# TLE985x register map
Vendor: Infineon Technologies AG; File version: 1.3
CPU: CM0 r0p0, little endian, no MPU, no FPU, 2 interrupt priority bits
Registers are 32-bit, read-write, no defined reset value unless marked. A register's access mark holds for its fields unless they carry their own. Offsets are from the block's base; [hi:lo] are bit positions; {n}, {i} and the like mark numbered series; 'fields as' and 'values as' point back to an identical list.

## PMU
Base 0x50004000
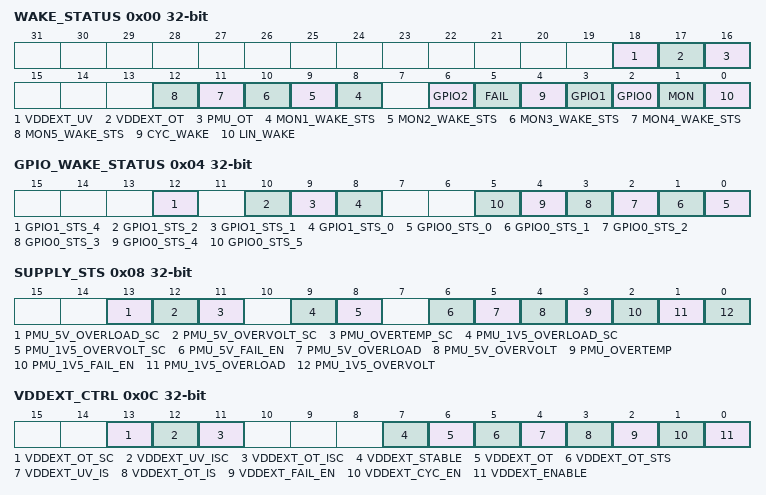
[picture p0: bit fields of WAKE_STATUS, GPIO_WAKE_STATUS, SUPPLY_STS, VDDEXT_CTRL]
0x00 WAKE_STATUS ro — Main wake status register
  [18] VDDEXT_UV — Wake VDDEXT Undervoltage
    0=No wake-up detected; 1=wake-up detected
  [17] VDDEXT_OT — Wake VDDEXT Overtemperature
    0=No wake-up detected; 1=wake-up detected
  [16] PMU_OT — Wake PMU Overtemperature
    0=No wake-up detected; 1=wake-up detected
  [n+7] MON{n}_WAKE_STS (n=1..5) — Status of MON{n}
    0=No wake-up detected; 1=wake-up detected
  [6] GPIO2 — Wake-up via GPIO2 which is a logical OR combination of all Wake_STS_GPIO2 bits
    0=No Wake-up occurred; 1=Wake-up occurred
  [5] FAIL — Wake-up after any Fail, which is a logical OR combination of PMU_OT, VDDEXT_OT, VDDEXT_UV
    0=No Wake-up occurred; 1=Wake-up occurred
  [4] CYC_WAKE — Wake-up caused by Cyclic Wake
    0=No Wake-up occurred; 1=Wake-up occurred
  [3] GPIO1 — Wake-up via GPIO1 which is a logical OR combination of all Wake_STS_GPIO1 bits
    0=No Wake-up occurred; 1=Wake-up occurred
  [2] GPIO0 — Wake-up via GPIO0 which is a logical OR combination of all Wake_STS_GPIO0 bits
    0=No Wake-up occurred; 1=Wake-up occurred
  [1] MON — Wake-up via MON which is a logical OR combination of all Wake_STS_MON bits
    0=No Wake-up occurred; 1=Wake-up occurred
  [0] LIN_WAKE — Wake-up via LIN- Message
    0=No Wake-up occurred; 1=Wake-up occurred
0x04 GPIO_WAKE_STATUS ro — GPIO Port wake status register
  [all] fields
    0=No wake-up detected; 1=wake-up detected
  [12] GPIO1_STS_4 — Wake GPIO1_4
  [10] GPIO1_STS_2 — Wake GPIO1_2
  [9] GPIO1_STS_1 — Wake GPIO1_1
  [8] GPIO1_STS_0 — Wake GPIO1_0
  [n] GPIO0_STS_{n} (n=0..5) — Status of GPIO0_{n}
0x08 SUPPLY_STS access per field — Voltage Reg Status Register
  [13] PMU_5V_OVERLOAD_SC wo — Overload at VDDP regulator Status clear
    0=No Clear (Overload status not cleared); 1=Clear (Overload status cleared)
  [12] PMU_5V_OVERVOLT_SC wo — Overvoltage at VDDP regulator Status clear
    0=No Clear (Overvoltage status not cleared); 1=Clear (Overvoltage status cleared)
  [11] PMU_OVERTEMP_SC wo — Overtemperature Status clear
    0=No Clear (Overtemperature status not cleared); 1=Clear (Overtemperature status cleared)
  [9] PMU_1V5_OVERLOAD_SC wo — Overload at VDDC regulator Status clear
    values as PMU_5V_OVERLOAD_SC
  [8] PMU_1V5_OVERVOLT_SC wo — Overvoltage at VDDC regulator Status clear
    values as PMU_5V_OVERVOLT_SC
  [6] PMU_5V_FAIL_EN rw — Enabling of VDDP status information as interrupt source
    0=Disable (No interrupts are generated); 1=Enable (Interrupts are generated)
  [5] PMU_5V_OVERLOAD ro — Overload at VDDP regulator
    0=No overload; 1=Overload
  [4] PMU_5V_OVERVOLT ro — Overvoltage at VDDP regulator
    0=No overvoltage; 1=Overvoltage
  [3] PMU_OVERTEMP ro — PMU Overtemperature
    0=No overtemperature; 1=Overtemperature
  [2] PMU_1V5_FAIL_EN rw — Enabling of VDDC status information as interrupt source
    values as PMU_5V_FAIL_EN
  [1] PMU_1V5_OVERLOAD ro — Overload at VDDC regulator
    0=No overload; 1=Overload
  [0] PMU_1V5_OVERVOLT ro — Overvoltage at VDDC regulator
    0=No overvoltage; 1=Overvoltage
0x0C VDDEXT_CTRL access per field — VDDEXT Control
  [13] VDDEXT_OT_SC wo — VDDEXT Supply Overtemperature Status clear
    1=No Clear (VDDEXT Overtemperature status not cleared); 0=Clear (VDDEXT Overtemperature status cleared)
  [12] VDDEXT_UV_ISC wo — VDDEXT Supply Undervoltage Interrupt Status clear
    1=No Clear (VDDEXT Undervoltage not cleared); 0=Clear (VDDEXT Undervoltage cleared)
  [11] VDDEXT_OT_ISC wo — VDDEXT Supply Overtemperature Interrupt Status clear
    1=No Clear (VDDEXT OverTemperature not cleared); 0=Clear (VDDEXT OverTemperature cleared)
  [7] VDDEXT_STABLE ro — VDDEXT Supply Stable
    0=VDDEXT not in stable condition; 1=VDDEXT in stable condition
  [6] VDDEXT_OT ro — VDDEXT Supply Overtemperature
    0=VDDEXT not in overtemperature condition; 1=VDDEXT in overtemperature condition
  [5] VDDEXT_OT_STS ro — VDDEXT Supply Overtemperature Status
    values as VDDEXT_OT
  [4] VDDEXT_UV_IS ro — VDDEXT Supply Undervoltage Interrupt Status
    0=VDDEXT not in undervoltage condition; 1=VDDEXT in undervoltage condition
  [3] VDDEXT_OT_IS ro — VDDEXT Supply OverTemperature Interrupt Status
    0=VDDEXT no overtemperature condition; 1=VDDEXT overtemperature condition
  [2] VDDEXT_FAIL_EN rw — Enabling of VDDEXT Supply status information as interrupt source
    0=Disable (VDDEXT fail interrupts are disable); 1=Enable (VDDEXT fail Interrupts are enable)
  [1] VDDEXT_CYC_EN rw — VDDEXT Supply for Cyclic Sense Enable
    0=Disable (VDDEXT for cyclic sense disable); 1=Enable (VDDEXT for cyclic sense enable)
  [0] VDDEXT_ENABLE rw — VDDEXT Supply Enable
    0=Disable (VDDEXT Supply disable); 1=Enable (VDDEXT supply enable)
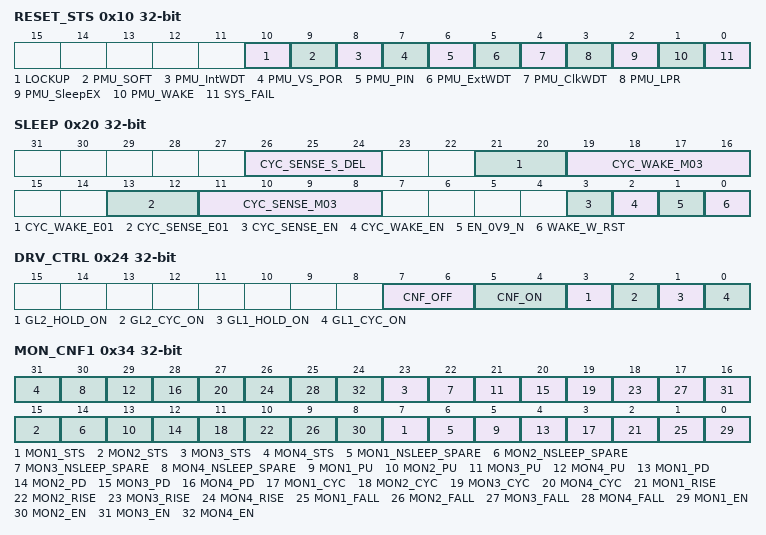
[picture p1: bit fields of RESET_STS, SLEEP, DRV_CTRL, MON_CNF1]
0x10 RESET_STS — Reset Status Register
  [10] LOCKUP — Lockup-Reset Flag
    0=No Reset (No Lockup-Reset executed); 1=Reset (Lockup-Reset executed)
  [9] PMU_SOFT — Soft-Reset Flag
    0=No Reset (No Soft-Reset executed); 1=Reset (Soft-Reset executed)
  [8] PMU_IntWDT — Internal Watchdog Reset Flag
    0=No Reset (No Internal Watchdog reset executed); 1=Reset (Internal Watchdog reset executed)
  [7] PMU_VS_POR — Power-On Reset Flag
    0=No Reset (No Power-On reset executed); 1=Reset (Power-On reset executed)
  [6] PMU_PIN — PIN-Reset Flag
    0=No Reset (No PIN-Reset executed); 1=Reset (PIN-Reset executed)
  [5] PMU_ExtWDT — External Watchdog (WDT1) Reset Flag
    0=No Reset (No External Watchdog reset executed); 1=Reset (External Watchdog reset executed)
  [4] PMU_ClkWDT — Clock Watchdog (CLKWDT) Reset Flag
    0=No Reset (No Clock Watchdog reset executed); 1=Reset (Clock Watchdog reset executed)
  [3] PMU_LPR — Low Priority Resets (see PMU_RST_STS2)
    0=No Reset (No Low Priority reset executed); 1=Reset (Low Priority reset executed)
  [2] PMU_SleepEX — Flag which indicates a reset caused by Sleep-Exit
    0=No reset caused by Sleep-Exit executed; 1=Reset caused by Sleep-Exit executed
  [1] PMU_WAKE — Flag which indicates a reset caused by Stop-Exit
    0=No reset caused by Stop-Exit executed; 1=Reset caused by Stop-Exit executed
  [0] SYS_FAIL — Flag which indicates a reset caused by a System Fail reported in the corresponding Fail Register
    0=No reset caused by System Fail executed; 1=Reset caused by System Fail executed
0x20 SLEEP — PMU Sleep Behavior Register
  [26:24] CYC_SENSE_S_DEL — Sample Delay in Cyclic Sense
    0=10 us typ; 1=20 us typ; 2=30 us typ; 3=40 us typ; 4=60 us typ; 5=80 us typ; 6=100 us typ; 7=150 us typ
  [21:20] CYC_WAKE_E01 — Exponent
    {v}=Exponent value is {v} (v=0..3)
  [19:16] CYC_WAKE_M03 — Mantissa
    0=Mantissa value is 1; 15=Mantissa value is 16
  [13:12] CYC_SENSE_E01 — Exponent
    {v}=Exponent value is {v} (v=0..3)
  [11:8] CYC_SENSE_M03 — Mantissa
    0=Mantissa value is 1; 15=Mantissa value is 16
  [3] CYC_SENSE_EN — Enabling Cyclic Sense
    0=Disable (Cyclic Sense disabled); 1=Enable (Cyclic Sense enabled)
  [2] CYC_WAKE_EN — Enabling Cyclic Wake
    0=Disable (Cyclic Wake disabled); 1=Enable (Cyclic Wake enabled)
  [1] EN_0V9_N — Enables the reduction of the VDDC regulator output to 0.9 V during Stop-Mode
    0=Enable (Output voltage reduction enabled); 1=Disable (Output voltage reduction disabled)
  [0] WAKE_W_RST — Wake-up with reset execution
    0=No Reset (Stop-Exit without reset execution); 1=Reset (Stop-Exit with reset execution)
0x24 DRV_CTRL — PMU Bridge Driver Control
  [7:6] CNF_OFF — CNF_OFF Function
    0=400 us; 1=800 us; 2=2000 us; 3=4000 us
  [5:4] CNF_ON — CNF_ON Function
    0=50 us; 1=100 us; 2=200 us; 3=400 us
  [3] GL2_HOLD_ON — GL2 Hold Mode On
    0=Disable; 1=Enable
  [2] GL2_CYC_ON — GL2 Cyclic On
    0=Disable; 1=Enable
  [1] GL1_HOLD_ON — GL1 Hold Mode On
    0=Disable; 1=Enable
  [0] GL1_CYC_ON — GL1 Cyclic On
    0=Disable; 1=Enable
0x34 MON_CNF1 access per field — Settings Monitor
  [8n-1] MON{n}_STS ro (n=1..4) — MON{n} Status Input
    0=Low (MON input has low status); 1=High (MON input has high status)
  [8n-2] MON{n}_NSLEEP_SPARE rw (n=1..4) — MON{n} Sleep Bit
    0=Sleep Mode (internal MON output forced to 0); 1=Active Mode (internal MON output not forced to 0)
  [8n-3] MON{n}_PU rw (n=1..4) — Pull-Up Current Source for MON{n} Input Enable
    0=Disable (Pull-up source disabled); 1=Enable (Pull-up source enabled)
  [8n-4] MON{n}_PD rw (n=1..4) — Pull-Down Current Source for MON{n} Input Enable
    0=Disable (Pull-down source disabled); 1=Enable (Pull-down source enabled)
  [8n-5] MON{n}_CYC rw (n=1..4) — MON{n} for Cycle Sense Enable
    0=Disable (Cycle Sense disabled); 1=Enable (Cycle Sense enabled)
  [8n-6] MON{n}_RISE rw (n=1..4) — MON{n} Wake-up on Rising Edge Enable
    0=Disable (Wake-up disabled); 1=Enable (Wake-up enabled)
  [8n-7] MON{n}_FALL rw (n=1..4) — MON{n} Wake-up on Falling Edge Enable
    0=Disable (Wake-up disabled); 1=Enable (Wake-up enabled)
  [8n-8] MON{n}_EN rw (n=1..4) — MON{n} Enable
    0=Disable (MON{n} disabled); 1=Enable (MON{n} enabled)
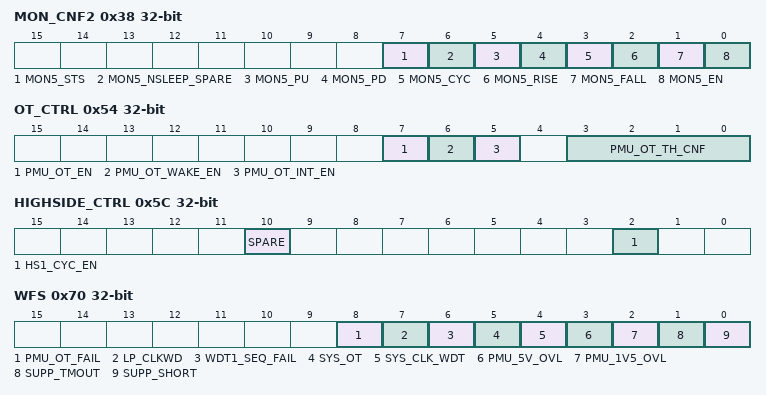
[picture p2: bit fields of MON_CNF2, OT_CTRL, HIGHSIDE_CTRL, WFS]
0x38 MON_CNF2 access per field — Settings Monitor
  [7] MON5_STS ro — MON5 Status Input
    values as MON_CNF1.MON1_STS
  [6] MON5_NSLEEP_SPARE rw — MON5 Sleep Bit
    values as MON_CNF1.MON1_NSLEEP_SPARE
  [5] MON5_PU rw — Pull-Up Current Source for MON5 Input Enable
    values as MON_CNF1.MON1_PU
  [4] MON5_PD rw — Pull-Down Current Source for MON5 Input Enable
    values as MON_CNF1.MON1_PD
  [3] MON5_CYC rw — MON5 for Cycle Sense Enable
    values as MON_CNF1.MON1_CYC
  [2] MON5_RISE rw — MON5 Wake-up on Rising Edge Enable
    0=Disable (Wake-up disabled); 1=Enable (Wake-up enabled)
  [1] MON5_FALL rw — MON5 Wake-up on Falling Edge Enable
    0=Disable (Wake-up disabled); 1=Enable (Wake-up enabled)
  [0] MON5_EN rw — MON5 Enable
    0=Disable (MON5 disabled); 1=Enable (MON5 enabled)
0x50 LIN_WAKE_EN — LIN Wake Enable
  [7] LIN_WAKE_EN — Lin Wake enable
    0=Wake Disabled; 1=Wake enabled
0x54 OT_CTRL — Overtemperature Control Register
  [7] PMU_OT_EN — PMU Overtemperature Detection Enable
    0=Disable (Overtemperature detection disabled); 1=Enable (Overtemperature detection enabled)
  [6] PMU_OT_WAKE_EN — PMU Wake On Overtemperature Enable
    0=Disable (no Wake-Up on OT condition); 1=Enable (Wake-Up on OT condition)
  [5] PMU_OT_INT_EN — PMU Overtemperature Interrupt Enable
    0=No Interrupt (Interrupt on OT disabled); 1=Interrupt on OT enabled
  [3:0] PMU_OT_TH_CNF — PMU Overtemperature threshold
    0=131 degree C; 1=136 degree C; 2=141 degree C; 3=146 degree C; 4=152 degree C; 5=157 degree C; 6=163 degree C; 7=169 degree C; 8=175 degree C; 9=181 degree C; 10=187 degree C; 11=193 degree C; 12=200 degree C; 13=206 degree C; 14=214 degree C; 15=221 degree C
0x5C HIGHSIDE_CTRL — Highside Control Register
  [10] SPARE
  [2] HS1_CYC_EN — High-Side 1 switch enable for cyclic sense
    0=Disable; 1=Enable
0x6C CNF_RST_TFB — Reset Blind Time Register
  [1:0] RST_TFB — Reset Pin Blind Time Selection Bits
    0=0.5 us typ; 1=1 us typ; 2=5 us typ; 3=31 us typ
0x70 WFS ro — WFS System Fail Register
  [8] PMU_OT_FAIL — PMU Overtemperature Indication Flag
    0=No Overtemperature (PMU ok); 1=Overtemperature (PMU Overtemperature)
  [7] LP_CLKWD
    0=ok; 1=fail
  [6] WDT1_SEQ_FAIL — External Watchdog (WDT1) Sequential Fail
    0=No Fail (System working properly); 1=Sequential Watchdog Fail (5 consecutive watchdog fails)
  [5] SYS_OT — System Overtemperature Indication Flag
    0=No Overtemperature (System ok); 1=Overtemperature (System Overtemperature)
  [4] SYS_CLK_WDT — System Clock (fsys)Watchdog Fail
    0=No System Clock Fail (fsys ok); 1=System Clock Fail (fsys failed)
  [3] PMU_5V_OVL — VDDP Overload Flag
    0=No Overload (VDDP ok); 1=Overload (VDDP Overload)
  [2] PMU_1V5_OVL — VDDC Overload Flag
    0=No Overload (VDDC ok); 1=Overload (Hall VDDC Overload)
  [1] SUPP_TMOUT — Supply Time Out
    0=Main Supply ok (VDDP or VDDC are in expected range); 1=Main Supply fail (VDDP or VDDC do not have stable operating point)
  [0] SUPP_SHORT — Supply Short
    0=Main Supply ok (VDDP or VDDC are in expected range); 1=Main Supply short (VDDP or VDDC are in short circuit condition)
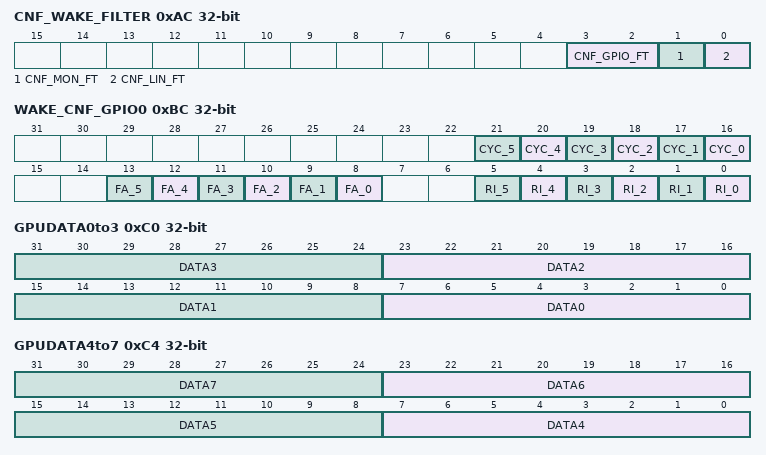
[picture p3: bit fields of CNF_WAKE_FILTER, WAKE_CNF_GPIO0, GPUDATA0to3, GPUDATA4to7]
0xAC CNF_WAKE_FILTER — PMU Wake-up Timing Register
  [3:2] CNF_GPIO_FT — Wake-up Filter time for General Purpose IO
    0=10 us filter time; 1=20 us filter time; 2=40 us filter time; 3=5 us filter time
  [1] CNF_MON_FT — Wake-up Filter time for Monitoring Inputs
    0=20 us filter time; 1=40 us filter time
  [0] CNF_LIN_FT — Wake-up Filter time for LIN WAKE
    0=50 us filter time; 1=30 us filter time
0xB4 PORCFG — POR Reset Configuration Register
  [1:0] CNF_FILT — Configuration for reset filter
0xBC WAKE_CNF_GPIO0 — Wake Configuration GPIO Port 0 Register
  [n+16] CYC_{n} (n=0..5) — GPIO0_{n} input for cycle sense enable
    1=ENABLE (input for cycle sense enabled); 0=DISABLE (input for cycle sense disabled)
  [n+8] FA_{n} (n=0..5) — Port 0_{n} Wake-up on Falling Edge enable
    1=ENABLE (wake-up enabled); 0=DISABLE (wake-up disabled)
  [n] RI_{n} (n=0..5) — Port 0_{n} Wake-up on Rising Edge enable
    1=ENABLE (wake-up enabled); 0=DISABLE (wake-up disabled)
0xC0 GPUDATA0to3 — General Purpose User DATA0to3
  [8n+7:8n] DATA{n} (n=0..3) — DATA{n} Storage Byte
0xC4 GPUDATA4to7 — General Purpose User DATA4to7
  [8n-25:8n-32] DATA{n} (n=4..7) — DATA{n} Storage Byte
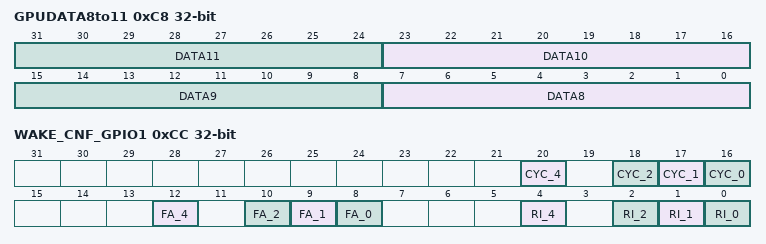
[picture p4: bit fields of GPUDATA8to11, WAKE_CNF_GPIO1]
0xC8 GPUDATA8to11 — General Purpose User DATA8to11
  [8n-57:8n-64] DATA{n} (n=8..11) — DATA{n} Storage Byte
0xCC WAKE_CNF_GPIO1 — Wake Configuration GPIO Port 1 Register
  [20] CYC_4 — GPIO1_4 input for cycle sense enable
    values as WAKE_CNF_GPIO0.CYC_0
  [18] CYC_2 — GPIO1_2 input for cycle sense enable
    values as WAKE_CNF_GPIO0.CYC_0
  [17] CYC_1 — GPIO1_1 input for cycle sense enable
    values as WAKE_CNF_GPIO0.CYC_0
  [16] CYC_0 — GPIO1_0 input for cycle sense enable
    values as WAKE_CNF_GPIO0.CYC_0
  [12] FA_4 — Port 1_4 Wake-up on Falling Edge enable
    1=ENABLE (wake-up enabled); 0=DISABLE (wake-up disabled)
  [10] FA_2 — Port 1_2 Wake-up on Falling Edge enable
    1=ENABLE (wake-up enabled); 0=DISABLE (wake-up disabled)
  [9] FA_1 — Port 1_1 Wake-up on Falling Edge enable
    1=ENABLE (wake-up enabled); 0=DISABLE (wake-up disabled)
  [8] FA_0 — Port 1_0 Wake-up on Falling Edge enable
    1=ENABLE (wake-up enabled); 0=DISABLE (wake-up disabled)
  [4] RI_4 — Port 1_4 Wake-up on Rising Edge enable
    1=ENABLE (wake-up enabled); 0=DISABLE (wake-up disabled)
  [2] RI_2 — Port 1_2 Wake-up on Rising Edge enable
    1=ENABLE (wake-up enabled); 0=DISABLE (wake-up disabled)
  [1] RI_1 — Port 1_1 Wake-up on Rising Edge enable
    1=ENABLE (wake-up enabled); 0=DISABLE (wake-up disabled)
  [0] RI_0 — Port 1_0 Wake-up on Rising Edge enable
    1=ENABLE (wake-up enabled); 0=DISABLE (wake-up disabled)
